# MCU_NAVSS0_UDMASS_UDMAP0_RCHAN register map
Vendor: Texas Instruments
Peripheral module from a debugger description file (folder J7ES).
Registers are 32-bit, read-write, reset 0x0 unless marked. A register's access mark holds for its fields unless they carry their own. Offsets are as the file gives them; lines under a group give offsets from that group; [hi:lo] are bit positions; {n}, {i} and the like mark numbered series; 'fields as' and 'values as' point back to an identical list; <NAME> marks a mode.

## MCU_NAVSS0_UDMASS_UDMAP0_RCHAN
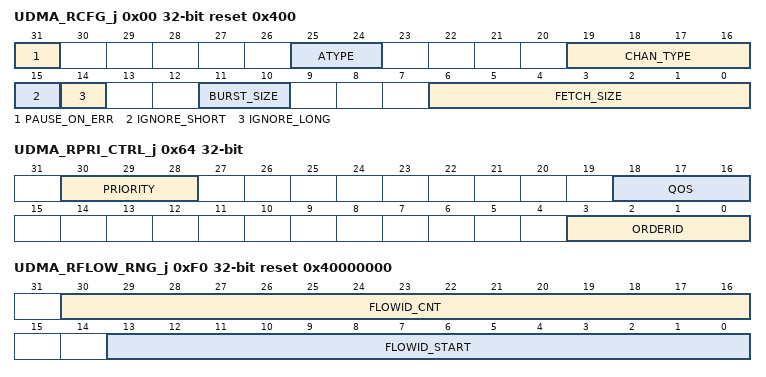
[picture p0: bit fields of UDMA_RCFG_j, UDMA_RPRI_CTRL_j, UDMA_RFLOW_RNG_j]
0x00 UDMA_RCFG_j reset 0x400 — The Rx Channel Configuration Register is used to initialize static mode settings for the Rx DMA channel. This register may only be written when the channel is disabled (rx_enable in realtime control reg is 0). Offset = 0h + (j * 100h); where j = 0h to 8B for NAVSS0_UDMASS_UDMAP0_CFG_RCHAN j = 0h to 2Fh for MCU_NAVSS0_UDMASS_UDMAP0_RCHAN
  [31] PAUSE_ON_ERR — Pause On Error: this field controls what the channel will do if an error or exception occurs during a data transfer. This field is encoded as follows: 0 = Channel will drop current work and move on 1 = Channel will pause and wait for SW to investigate and un-pause the channel.
  [25:24] ATYPE — This field controls how pointers will be interpreted for non Ring Accelerator accesses on this channel. The values are encoded as follows: 0 = Pointers are physical addresses 1 = Pointers are intermediate addresses which require intermediate to physical transaction before they can be decoded 2 = Pointers are virtual addresses which require virtual to physical translation before they can be decoded. All transactions from this channel which are not destined to the Ring Accelerator will have the mem*_catype attribute set equal to the value given in this register field. Accesses to the RA will always use physical addresses.
  [19:16] CHAN_TYPE — Rx Channel Type: this field controls and / or indicates the functional channel type for this channel and the work passing mechanism that the channel uses for communicating with the Host. Available channel types are as follows: 0 = RESERVED 1 = RESERVED 2 = Channel performs packet oriented data transfers using pass by reference rings. Channels configured in this mode can only use Host and Monolithic descriptors and the pointers to those descriptors are passed from/to SW using rings in the Ring Accelerator. 3 = Channel performs packet oriented data transfers using pass by reference rings with single buffer packet mode enabled. Channels configured in this mode can only use Host descriptors and each descriptor will be processed as an independent packet (no buffer chaining). This is the only packet oriented mode that can be used with data sources that are infinite streams (no EOP) 4 - 9 = RESERVED 10 = Channel performs Third Party DMA control transfers using pass by reference rings. Channels configured in this mode can only use TR descriptors and the pointers to those descriptors are passed from/to SW using rings in the Ring Accelerator. 11 = Channel performs Third Party DMA control transfers using pass by value rings. Channels configured in this mode will directly pass individual Transfer Request/Transfer Response messages from/to SW using rings in the Ring Accelerator. 12 = Channel performs Third Party Block Copy DMA control transfers using pass by reference rings. Channels configured in this mode are linked to the same index Rx channel to form a bonded read/write channel 13 = Channel performs Third Party Block Copy DMA data transfers using pass by reference rings. Channels configured in this mode are linked to the same index Rx channel to form a bonded read/write channel 14 = Channel performs Third Party DMA data transfers using TRs provided via PSI-L (not supported in UDMA-P). 15 = Channel performs Third Party DMA data transfers using TRs provided via QDMA channel (not supported in UDMA-P)
  [15] IGNORE_SHORT — This field controls whether or not short packets will be treated as exceptions or ignored for the channel. This field is only used when the channel is in split UTC mode. The values are encoded as follows: 0 = Short packets are treated as exceptions and handled appropriately. 1 = Short packets are ignored and the TR will continue to execute even if an EOP is encountered prematurely or the TR does not have EOP set.
  [14] IGNORE_LONG — This field controls whether or not long packets will be treated as exceptions or ignored for the channel. This field is only used when the channel is in split UTC mode. The values are encoded as follows: 0 = Long packets are treated as exceptions and handled appropriately. 1 = Long packets are ignored and the next TR will be fetched even if the current TR is marked or interpreted as EOP.
  [11:10] BURST_SIZE — Specifies the nominal burst size and alignment for data transfers on this channel.
  [6:0] FETCH_SIZE — Specifies the # of 32-bit descriptor words to fetch. This must be set to the maximum word count that can pass through the channel for any allowed descriptor type.
0x14 UDMA_RCQ_j — The Rx Channel Completion Queue Register is used to specify which queue the Transfer Responses will be returned to when operating in the pass by value TR based channel mode. This register may only be written when the channel is disabled (tx_enable in realtime control reg is 0). Offset = 14h + (j * 100h); where j = 0h to 8B for NAVSS0_UDMASS_UDMAP0_CFG_RCHAN j = 0h to 2Fh for MCU_NAVSS0_UDMASS_UDMAP0_RCHAN
  [15:0] RXCQ_QNUM — Specifies the queue number to return pass by value Transfer Responses and teardown completion teardown messages to.
0x20 UDMA_ROES_j reset 0xFFFF — The Output Event Steering Registers are used to specify a global event number to generate anytime the required event generation criteria specified in a TR are met. A single event with the event number set equal to the value in the corresponding register will be generated. This register is provided in order to allow security SW to lock down which events in the global space any given channel/ thread is allowed to generate. Offset = 20h + (j * 100h); where j = 0h to 8B for NAVSS0_UDMASS_UDMAP0_CFG_RCHAN j = 0h to 2Fh for MCU_NAVSS0_UDMASS_UDMAP0_RCHAN
  [15:0] EVT_NUM — This is the global event number to be generated
0x60 UDMA_REOES_j reset 0xFFFF — The Error Output Event Steering Registers are used to specify a global event number to generate anytime an error is encountered on the channel. A single event with the event number set equal to the value in the corresponding register will be generated. This register is provided in order to allow security SW to lock down which events in the global space any given channel/ thread is allowed to generate. Offset = 60h + (j * 100h); where j = 0h to 8B for NAVSS0_UDMASS_UDMAP0_CFG_RCHAN j = 0h to 2Fh for MCU_NAVSS0_UDMASS_UDMAP0_RCHAN
  [15:0] EVT_NUM — This is the global event number to be generated
0x64 UDMA_RPRI_CTRL_j — The priority control register is used to control the priority of the transactions which the DMA generates on it's master interface. Offset = 64h + (j * 100h); where j = 0h to 8B for NAVSS0_UDMASS_UDMAP0_CFG_RCHAN j = 0h to 2Fh for MCU_NAVSS0_UDMASS_UDMAP0_RCHAN
  [30:28] PRIORITY — Rx Priority: This field contains the 3-bit value which will be output on the mem*_cpriority and mem*_cepriority outputs during all transactions for this channel.
  [18:16] QOS — Rx Quality of Service Level: This field contains the 3-bit value which will be output on the mem*_cqos output during all transactions for this channel.
  [3:0] ORDERID — Rx Order ID: This field contains the 4-bit value which will be output on the mem*_corderid output during all transactions for this channel.
0x68 UDMA_THREAD_j — The thread ID mapping register is used to pair the Rx DMA channel to a specific destination thread. All traffic generated from this channel will be sent with a thread_id on the PSI-L interface with the value from this register. Offset = 68h + (j * 100h); where j = 0h to 95h j = 0h to 8B for NAVSS0_UDMASS_UDMAP0_CFG_RCHAN j = 0h to 2Fh for MCU_NAVSS0_UDMASS_UDMAP0_RCHAN
  [15:0] ID — Thread ID: This field contains the 16-bit value which will be output on the strm_o_thread_id output during all transactions for this channel.
0x80 UDMA_RST_SCHED_j — The Rx Channel N Static Scheduler Configuration Register contains static configuration information which affects the conditions under which each channel will be given an opportunity to use the Tx DMA unit(s). The fields in this register are as follows: Offset = 80h + (j * 100h); where j = 0h to 95h j = 0h to 8B for NAVSS0_UDMASS_UDMAP0_CFG_RCHAN j = 0h to 2Fh for MCU_NAVSS0_UDMASS_UDMAP0_RCHAN
  [1:0] PRIORITY — Rx Scheduling Priority: These bits select which scheduling bin the channel will be placed in for bandwidth allocation of the Rx DMA units. This field is encoded as follows: 0 = High priority 1 = Medium - high priority 2 = Medium - low priority 3 = Low priority Arbitration between bins is performed in a strict priority fashion. High priority channels will always be serviced first. If no high priority channels are requesting then all medium-high priority channels will be serviced next. If no high priority or medium-high priority channels are requesting then all medium-low priority channels will be serviced next. When no other channels are requesting, the low priority channels will be serviced. All channels within a given bin are serviced in a round robin order. Only channels which are enabled and which have sufficient free space in their Per Channel FIFO will be included in the round robin arbitration.
0xF0 UDMA_RFLOW_RNG_j reset 0x40000000 — The flow range register is used to control which flows other than the default flow (0x3FFF / channel_number) are allowed to be used with this DMA channel. Offset = F0h + (j * 100h); where j = 0h to 8B for NAVSS0_UDMASS_UDMAP0_CFG_RCHAN j = 0h to 2Fh for MCU_NAVSS0_UDMASS_UDMAP0_RCHAN
  [30:16] FLOWID_CNT — Rx Flow ID Count: This field specifies how many flow IDs are in the additional contiguous range of legal flow IDs for this channel. A value of 0 indicates that no flow IDs other than the default are allowed for the channel..
  [13:0] FLOWID_START — Rx Starting Flow ID: Beyond the default flow ID, each channel can also make use of a single contiguous range of flow IDs and this field specifies the starting index for that range..
